# BlueNRG_LP register map
File version: 1.0
CPU: CM0+ r0p0, little endian, no MPU, no FPU, 2 interrupt priority bits
Registers are 32-bit, read-write, reset 0x0 unless marked. A register's access mark holds for its fields unless they carry their own. Offsets are from the block's base; [hi:lo] are bit positions; {n}, {i} and the like mark numbered series.

## PWR — Power control
Base 0x48500000
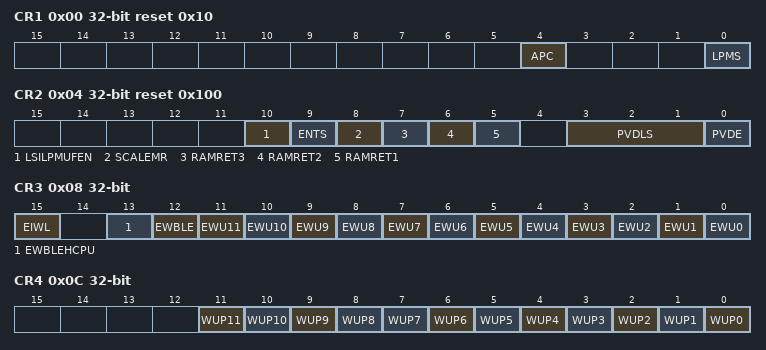
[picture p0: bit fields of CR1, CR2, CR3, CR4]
0x00 CR1 reset 0x10 — Power control register 1
  [4] APC — Apply Pull-up and pull-down configuration from CPU
  [0] LPMS — Low Power Mode Selection
0x04 CR2 reset 0x100 — Power control register 2
  [10] LSILPMUFEN — LSI LPMU Force ENable
  [9] ENTS — Enable Temperature Sensor
  [8] SCALEMR — Voltage scaling Main Regulator Selection.
  [7] RAMRET3 — RAM3 retention during low power mode
  [6] RAMRET2 — RAM2 retention during low power mode
  [5] RAMRET1 — RAM1 retention during low power mode
  [3:1] PVDLS — Programmable Voltage Detector Level selection
  [0] PVDE — Programmable Voltage Detector Enable
0x08 CR3 — Power control register 3
  [15] EIWL — Enable internal WakeUp line
  [13] EWBLEHCPU — EWBLEHCPU Wakeup BLE Host CPU Enable
  [12] EWBLE — Wakeup BLE Enable
  [n] EWU{n} (n=0..11) — Enable WakeUp line {n}
0x0C CR4 — Power control register 4
  [11] WUP11 — Wakeup polarity for PA11 I/O.
  [10] WUP10 — Wakeup polarity for PA10 I/O.
  [9] WUP9 — Wakeup polarity for PA9 IO event.
  [8] WUP8 — Wakeup polarity for PA8 IO event.
  [n] WUP{n} (n=0..7) — Wakeup polarity for PB{n} IO event.
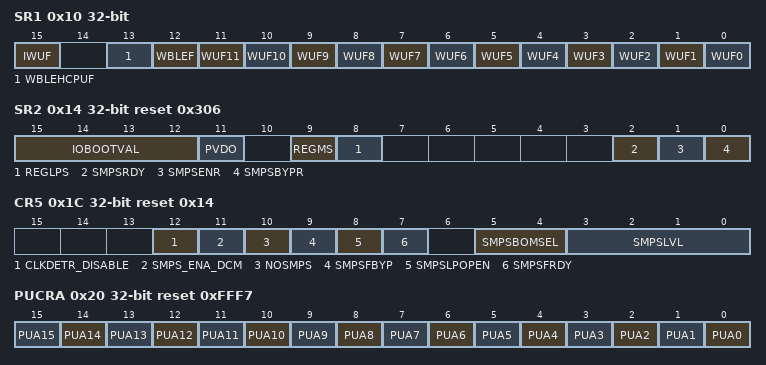
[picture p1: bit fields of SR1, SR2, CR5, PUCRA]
0x10 SR1 — Power status register 1
  [15] IWUF — WakeUp Flag Internal
  [13] WBLEHCPUF — Wakeup BLE HOST CPU Flag (cf. user manual)
  [12] WBLEF — Wakeup BLE Flag
  [n] WUF{n} (n=0..11) — WakeUp Flag {n}
0x14 SR2 ro reset 0x306 — Power status register 2
  [15:12] IOBOOTVAL
  [11] PVDO — Power Voltage Detector Output
  [9] REGMS — Regulator Main LDO Started
  [8] REGLPS — Regulator Low Power Started
  [2] SMPSRDY — SMPS Ready Status
  [1] SMPSENR — SMPS Enable Control Replica
  [0] SMPSBYPR — SMPS Force Bypass Control Replica
0x1C CR5 reset 0x14 — Power control register 5
  [12] CLKDETR_DISABLE — disable the SMPS clock detection
  [11] SMPS_ENA_DCM — Discontinuous conduction mode enable.
  [10] NOSMPS — No SMPS Mode
  [9] SMPSFBYP — Force SMPS Regulator in bypass mode
  [8] SMPSLPOPEN — In Low Power mode SMPS is in OPEN mode (instead of PRECHARGE mode).
  [7] SMPSFRDY — Force ready check
  [5:4] SMPSBOMSEL — SMPS BOM Selection
  [3:0] SMPSLVL — SMPS Output Level Voltage Selection
0x20 PUCRA reset 0xFFF7 — Power Port A pull-up control register
  [n] PUA{n} (n=0..15) — Port A PAll-up bit {n}
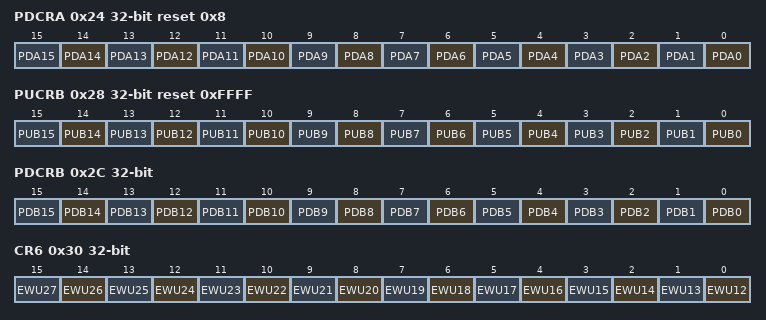
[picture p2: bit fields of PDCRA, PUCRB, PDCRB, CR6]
0x24 PDCRA reset 0x8 — Power Port A pull-down control register
  [n] PDA{n} (n=0..15) — Port A pull-down bit {n}
0x28 PUCRB reset 0xFFFF — Power Port B pull-up control register
  [n] PUB{n} (n=0..15) — Port B PBll-up bit {n}
0x2C PDCRB — Power Port B pull-down control register
  [n] PDB{n} (n=0..15) — Port B pull-down bit {n}
0x30 CR6 — This register manages the selection of the wakeup sources to get out of DEEPSTOP mode
  [n-12] EWU{n} (n=24..27) — Enable wakeup on PA{n-12} I/O event.
  [n-12] EWU{n} (n=20..23) — Enable wakeup on PB{n-12} I/O event.
  [n-12] EWU{n} (n=12..19) — Enable wakeup on PA{n-12} I/O event.
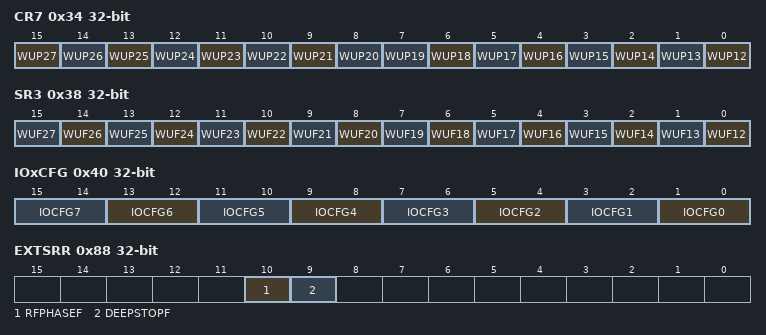
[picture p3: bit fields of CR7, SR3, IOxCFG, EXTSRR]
0x34 CR7 — This register manages the polarity for the I/Os wakeup sources to get out of DEEPSTOP
  [15] WUP27 — Wakeup polarity for PA15 I/O.
  [14] WUP26 — Wakeup polarity for PA14 I/O.
  [13] WUP25 — Wakeup polarity for PA13 IO event.
  [12] WUP24 — Wakeup polarity for PA12 I/O.
  [11] WUP23 — Wakeup polarity for PB11 I/O.
  [10] WUP22 — Wakeup polarity for PB10 I/O.
  [9] WUP21 — Wakeup polarity for PB9 IO event.
  [8] WUP20 — Wakeup polarity for PB8 IO event.
  [n-12] WUP{n} (n=12..19) — Wakeup polarity for PA{n-12} IO event.
0x38 SR3 — This register provides the information concerning which source woke up the device after a DEEPSTOP.
  [n-12] WUF{n} (n=24..27) — PA{n-12} I/O wakeup flag.
  [n-12] WUF{n} (n=20..23) — PB{n-12} I/O wakeup flag.
  [n-12] WUF{n} (n=12..19) — PA{n-12} I/O wakeup flag.
0x40 IOxCFG — IO DEEPSTOP drive configuration register
  [2n+1:2n] IOCFG{n} (n=4..7) — Drive configuration for PA{n}.
  [2n+1:2n] IOCFG{n} (n=0..3) — Drive configuration for PA{n+8}.
0x84 DBGR — This register is used for debug features
  [0] DEEPSTOP2 — DEEPSTOP2 low power saving emulation enable.
0x88 EXTSRR — Power status clear register
  [10] RFPHASEF — RFPHAS Flag
  [9] DEEPSTOPF — System DeepStop Flag
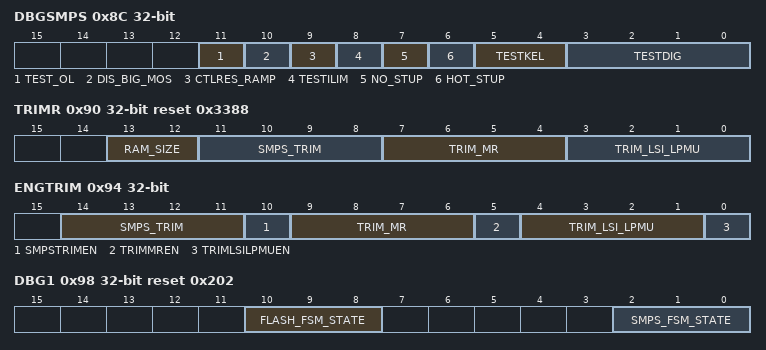
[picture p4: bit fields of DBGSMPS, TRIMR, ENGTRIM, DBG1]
0x8C DBGSMPS — This register drives some control signals for the SMPS
  [11] TEST_OL — TEST_OL_3V3 SMPS control signal.
  [10] DIS_BIG_MOS — DIS_BIG_MOS_3V3 SMPS control signal.
  [9] CTLRES_RAMP — CTLRES_RAMP_3V3 SMPS control signal.
  [8] TESTILIM — SMPS_TEST_ILIM_3V3 control signal.
  [7] NO_STUP — NO_STUP_3V3 SMPS control signal.
  [6] HOT_STUP — HOT_STUP_3V3 SMPS control signal.
  [5:4] TESTKEL — SMPS_TEST_KEL_3V3[2:0] control bus.
  [3:0] TESTDIG — SMPS_TEST_DIG_3V3[3:0] control bus.
0x90 TRIMR ro reset 0x3388 — This register provides the trimming values applied by hardware according to the trimming done at EWS.
  [13:12] RAM_SIZE — Indicates the RAM size available in the device.
  [11:8] SMPS_TRIM
  [7:4] TRIM_MR — Main regulator voltage trimming.
  [3:0] TRIM_LSI_LPMU — LPMU low speed internal oscillator trimming.
0x94 ENGTRIM — This register allows the software overloading the hardware trimming flashed at EWS.
  [14:11] SMPS_TRIM — SMPS output voltage trimming chosen by the software.
  [10] SMPSTRIMEN — SMPS_TRIM software overload enable.
  [9:6] TRIM_MR — Main regulator voltage trimming chosen by the software.
  [5] TRIMMREN — TRIM_MR software overload enable.
  [4:1] TRIM_LSI_LPMU — LPMU low speed internal oscillator trimming chosen by the software.
  [0] TRIMLSILPMUEN — TRIM_LSI_LPMU software overload enable.
0x98 DBG1 ro reset 0x202 — This register shows the current states of the FLASH FSM and SMPS FSM.
  [10:8] FLASH_FSM_STATE — Indicates the current state of the FLASH FSM inside the PWRC
  [2:0] SMPS_FSM_STATE — Indicates the current state of the SMPS FSM inside the PWRC.
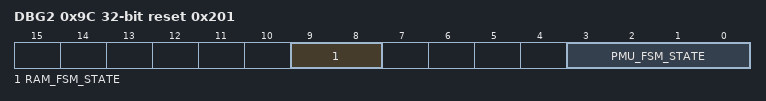
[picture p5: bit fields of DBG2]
0x9C DBG2 ro reset 0x201 — This register shows the current states of the FLASH FSM and SMPS FSM.
  [9:8] RAM_FSM_STATE — Indicates the current state of the RAM FSM inside the PWRC
  [3:0] PMU_FSM_STATE — Indicates the current state of the PMU FSM inside the PWRC.
